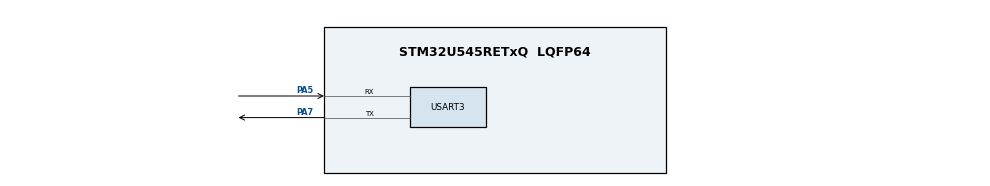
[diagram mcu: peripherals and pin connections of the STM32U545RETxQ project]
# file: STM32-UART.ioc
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CORTEX_M33_NS.userName=CORTEX_M33
GPDMA1.CIRCULARMODE_GPDMACH10=ENABLE
GPDMA1.DESTINC_GPDMACH10=DMA_DINC_INCREMENTED
GPDMA1.DIRECTION_GPDMACH11=DMA_MEMORY_TO_PERIPH
GPDMA1.IPHANDLE_GPDMACH10-SIMPLEREQUEST_GPDMACH10=__NULL
GPDMA1.IPHANDLE_GPDMACH11-SIMPLEREQUEST_GPDMACH11=__NULL
GPDMA1.LINKALLOCATEDPORT_CIRCULAR_GPDMACH10=DMA_LINK_ALLOCATED_PORT1
GPDMA1.REQUEST_GPDMACH10=GPDMA1_REQUEST_USART3_RX
GPDMA1.REQUEST_GPDMACH11=GPDMA1_REQUEST_USART3_TX
GPDMA1.SRCINC_GPDMACH11=DMA_SINC_INCREMENTED
GPDMA1.TRANSFERALLOCATEDPORTDEST_GPDMACH10=DMA_DEST_ALLOCATED_PORT1
GPDMA1.TRANSFERALLOCATEDPORTSRC_GPDMACH10=DMA_SRC_ALLOCATED_PORT1
Mcu.Family=STM32U5
Mcu.Name=STM32U545RETxQ
Mcu.Package=LQFP64
NUCLEO-U545RE-Q.Bsp_Common_DEMO=true
NUCLEO-U545RE-Q.VCP=true
NVIC.GPDMA1_Channel10_IRQn=true\:0\:0\:false\:false\:true\:false\:true\:true
NVIC.GPDMA1_Channel11_IRQn=true\:0\:0\:false\:false\:true\:false\:true\:true
NVIC.PriorityGroup=NVIC_PRIORITYGROUP_4
NVIC.USART3_IRQn=true\:0\:0\:false\:false\:true\:true\:true\:true
PA13\ (JTMS/SWDIO).Mode=Serial_Wire
PA13\ (JTMS/SWDIO).Signal=DEBUG_JTMS-SWDIO
PA14\ (JTCK/SWCLK).Mode=Serial_Wire
PA14\ (JTCK/SWCLK).Signal=DEBUG_JTCK-SWCLK
PA5.Mode=Asynchronous
PA5.Signal=USART3_RX
PA7.Mode=Asynchronous
PA7.Signal=USART3_TX
PWR.PowerMode=PWR_SMPS_SUPPLY
ProjectManager.HeapSize=0x200
ProjectManager.StackSize=0x400
ProjectManager.TargetToolchain=STM32CubeIDE
RCC.ADCFreq_Value=16000000
RCC.DACCLockSelectionVirtual=RCC_DAC1CLKSOURCE_LSI
RCC.DACCLockSelectionVirtualString=RCC_DAC1CLKSOURCE_LSI
RCC.EPOD_VALUE=16000000
RCC.HSE_VALUE=16000000
RCC.HSI48_VALUE=48000000
RCC.HSI_VALUE=16000000
RCC.LSE_VALUE=32768
RCC.LSIDIV_VALUE=32000
RCC.MSI_VALUE=4000000
RCC.PLLSourceVirtual=RCC_PLLSOURCE_HSI
RCC.USBFreq_Value=48000000
RCC.VCOOutputFreq_Value=2064000000
USART3.VirtualMode-Asynchronous=VM_ASYNC
VP_GPDMA1_VS_GPDMACH10.Mode=SIMPLEREQUEST_GPDMACH10
VP_GPDMA1_VS_GPDMACH11.Mode=SIMPLEREQUEST_GPDMACH11
VP_ICACHE_VS_ICACHE.Mode=DirectMappedCache
VP_LPBAMQUEUE_VS_QUEUE.Mode=QUEUEMODE
VP_LPBAM_VS_SIG1.Mode=SmartRun
VP_LPBAM_VS_SIG4.Mode=LPDMA1
VP_MEMORYMAP_VS_MEMORYMAP.Mode=CurAppReg
VP_NUCLEO-U545RE-Q_VS_BSP_COMMON.Mode=COMMON
VP_PWR_VS_LPOM.Mode=PowerOptimisation
VP_PWR_VS_SECSignals.Mode=Security/Privilege
board=NUCLEO-U545RE-Q

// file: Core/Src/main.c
/* USER CODE BEGIN Header */
/**
  ******************************************************************************
  * @file           : main.c
  * @brief          : Main program body
  ******************************************************************************
  * @attention
  *
  * Copyright (c) 2024 STMicroelectronics.
  * All rights reserved.
  *
  * This software is licensed under terms that can be found in the LICENSE file
  * in the root directory of this software component.
  * If no LICENSE file comes with this software, it is provided AS-IS.
  *
  ******************************************************************************
  */
/* USER CODE END Header */
#include "main.h"
#include "gpdma.h"
#include "icache.h"
#include "memorymap.h"
#include "usart.h"
#include "gpio.h"

/* USER CODE BEGIN Includes */
#include <string.h>
#include <stdio.h>
/* USER CODE END Includes */

COM_InitTypeDef BspCOMInit;
__IO uint32_t BspButtonState = BUTTON_RELEASED;

void SystemClock_Config(void);
static void SystemPower_Config(void);

/* USER CODE BEGIN 0 */
uint8_t rx_buff[10];
volatile uint8_t received = 0;

/* USER CODE END 0 */

int main(void)
{

  /* USER CODE BEGIN 1 */
	const char message[] = "Received data from UART\n\r";
  /* USER CODE END 1 */

  /* MCU Configuration--------------------------------------------------------*/

  /* Reset of all peripherals, Initializes the Flash interface and the Systick. */
  HAL_Init();

  /* Configure the system clock */
  SystemClock_Config();

  /* Configure the System Power */
  SystemPower_Config();

  /* Initialize all configured peripherals */
  MX_GPIO_Init();
  MX_GPDMA1_Init();
  MX_ICACHE_Init();
  MX_USART3_UART_Init();
  /* USER CODE BEGIN 2 */
  HAL_UART_Receive_DMA(&huart3, rx_buff, 10);
  /* USER CODE END 2 */

  /* Initialize COM1 port (115200, 8 bits (7-bit data + 1 stop bit), no parity */
  BspCOMInit.BaudRate   = 115200;
  BspCOMInit.WordLength = COM_WORDLENGTH_8B;
  BspCOMInit.StopBits   = COM_STOPBITS_1;
  BspCOMInit.Parity     = COM_PARITY_NONE;
  BspCOMInit.HwFlowCtl  = COM_HWCONTROL_NONE;
  if (BSP_COM_Init(COM1, &BspCOMInit) != BSP_ERROR_NONE)
  {
    Error_Handler();
  }

  /* USER CODE BEGIN BSP */

  /* -- Sample board code to send message over COM1 port ---- */
  printf("Hello using printf\n\r");
  /* USER CODE END BSP */

  /* Infinite loop */
  while (1)
  {
    /* USER CODE BEGIN 3 */
	  if(received == 1){
	  	HAL_UART_Transmit_DMA(&huart3, (uint8_t*)message, sizeof(message)-1);
	  	received = 0;
	  }
  }
  /* USER CODE END 3 */
}

void SystemClock_Config(void)
{
  RCC_OscInitTypeDef RCC_OscInitStruct = {0};
  RCC_ClkInitTypeDef RCC_ClkInitStruct = {0};

  /** Configure the main internal regulator output voltage
  */
  if (HAL_PWREx_ControlVoltageScaling(PWR_REGULATOR_VOLTAGE_SCALE4) != HAL_OK)
  {
    Error_Handler();
  }

  /** Initializes the CPU, AHB and APB buses clocks
  */
  RCC_OscInitStruct.OscillatorType = RCC_OSCILLATORTYPE_MSI;
  RCC_OscInitStruct.MSIState = RCC_MSI_ON;
  RCC_OscInitStruct.MSICalibrationValue = RCC_MSICALIBRATION_DEFAULT;
  RCC_OscInitStruct.MSIClockRange = RCC_MSIRANGE_4;
  RCC_OscInitStruct.PLL.PLLState = RCC_PLL_NONE;
  if (HAL_RCC_OscConfig(&RCC_OscInitStruct) != HAL_OK)
  {
    Error_Handler();
  }

  /** Initializes the CPU, AHB and APB buses clocks
  */
  RCC_ClkInitStruct.ClockType = RCC_CLOCKTYPE_HCLK|RCC_CLOCKTYPE_SYSCLK
                              |RCC_CLOCKTYPE_PCLK1|RCC_CLOCKTYPE_PCLK2
                              |RCC_CLOCKTYPE_PCLK3;
  RCC_ClkInitStruct.SYSCLKSource = RCC_SYSCLKSOURCE_MSI;
  RCC_ClkInitStruct.AHBCLKDivider = RCC_SYSCLK_DIV1;
  RCC_ClkInitStruct.APB1CLKDivider = RCC_HCLK_DIV1;
  RCC_ClkInitStruct.APB2CLKDivider = RCC_HCLK_DIV1;
  RCC_ClkInitStruct.APB3CLKDivider = RCC_HCLK_DIV1;

  if (HAL_RCC_ClockConfig(&RCC_ClkInitStruct, FLASH_LATENCY_0) != HAL_OK)
  {
    Error_Handler();
  }
}

/**
  * @brief Power Configuration
  * @retval None
  */
static void SystemPower_Config(void)
{

  /*
   * Switch to SMPS regulator instead of LDO
   */
  if (HAL_PWREx_ConfigSupply(PWR_SMPS_SUPPLY) != HAL_OK)
  {
    Error_Handler();
  }
}

/* USER CODE BEGIN 4 */
void HAL_UART_RxCpltCallback(UART_HandleTypeDef *huart)
{
	if(huart == &huart3){
		// HAL_UART_Transmit_DMA(&huart1,(uint8_t *) "Message Received!\r\n", sizeof("Message Received!\r\n"));
		HAL_UART_Receive_DMA(&huart3, rx_buff, 10);
		received = 1;
		HAL_UART_Receive_DMA(&huart3, rx_buff, 10);

	}

}
/* USER CODE END 4 */

void Error_Handler(void)
{
  __disable_irq();
  while (1)
  {
  }
}
